# TMS320F280049 register map
Vendor: Texas Instruments; Series: C2000 F28004x; File version: 0.2.0-generated
Registers are 16-bit, read-write, reset 0x0 unless marked. A register's access mark holds for its fields unless they carry their own. Offsets are from the block's base; [hi:lo] are bit positions.

## LINAREGS — LIN Registers
Base 0x0000D400
0x00 SCIGCR0 32-bit — Global Control Register 0
  [0] RESET — LIN Module reset bit
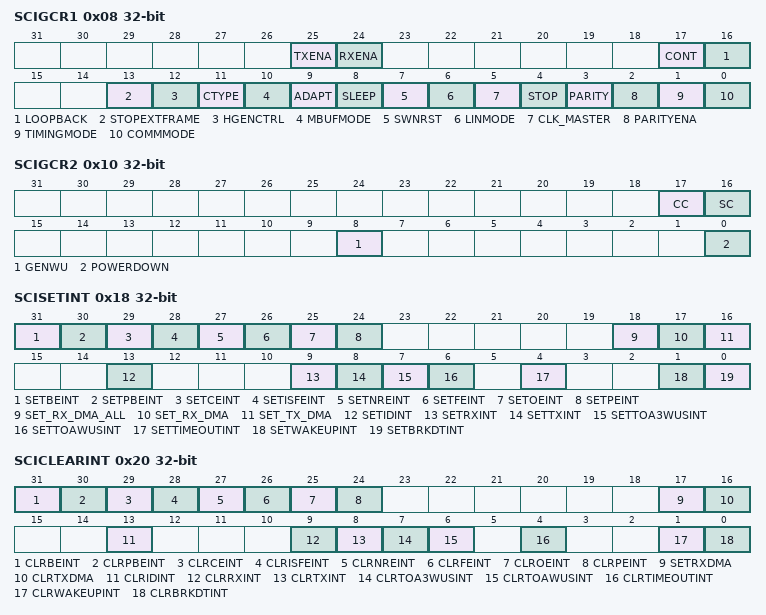
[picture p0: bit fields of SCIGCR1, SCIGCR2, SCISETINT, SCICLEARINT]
0x08 SCIGCR1 32-bit — Global Control Register 1
  [25] TXENA — Transmit enable
  [24] RXENA — Receive enable
  [17] CONT — Continue on suspend
  [16] LOOPBACK — Digital loopback mode
  [13] STOPEXTFRAME — Stop extended frame communication (LIN mode)
  [12] HGENCTRL — Mask filtering comparison control (LIN mode)
  [11] CTYPE — Checksum type (LIN mode)
  [10] MBUFMODE — Multi-buffer mode
  [9] ADAPT — Automatic baudrate adjustment control(LIN mode)
  [8] SLEEP — SCI sleep (SCI compatibility mode)
  [7] SWNRST — Software reset
  [6] LINMODE — LIN Mode enable/disable
  [5] CLK_MASTER — LIN Master/Slave selection and SCI clock enable
  [4] STOP — SCI number of stop bits
  [3] PARITY — SCI parity odd/even selection
  [2] PARITYENA — Parity enable
  [1] TIMINGMODE — SCI timing mode bit. Should be set to 1 for SCI mode.
  [0] COMMMODE — SCI/LIN communications mode bit
0x10 SCIGCR2 32-bit — Global Control Register 2
  [17] CC — Compare Checksum (LIN mode)
  [16] SC — Send Checksum (LIN mode)
  [8] GENWU — Generate Wakeup
  [0] POWERDOWN — Low-power mode PowerDown bit
0x18 SCISETINT 32-bit — Interrupt Enable Register
  [31] SETBEINT — Set Bit Error Interrupt (LIN only)
  [30] SETPBEINT — Set Physical Bus Error Interrupt (LIN only)
  [29] SETCEINT — Set Checksum-error Interrupt (LIN only)
  [28] SETISFEINT — Set Inconsistent-Sync-Field-Error Interrupt (LIN only)
  [27] SETNREINT — Set No-Response-Error Interrupt (LIN only)
  [26] SETFEINT — Set Framing-Error Interrupt
  [25] SETOEINT — Set Overrun-Error Interrupt
  [24] SETPEINT — Set Parity Interrupt
  [18] SET_RX_DMA_ALL — Set receiver DMA for Address and Data frames
  [17] SET_RX_DMA — Set receiver DMA
  [16] SET_TX_DMA — Set transmit DMA
  [13] SETIDINT — Set Identifier Interrupt (LIN only)
  [9] SETRXINT — Se Receiver Interrupt
  [8] SETTXINT — Set Transmitter Interrupt
  [7] SETTOA3WUSINT — Set Timeout After 3 Wakeup Signals Interrupt (LIN only)
  [6] SETTOAWUSINT — Set Timeout After Wakeup Signal Interrupt (LIN only)
  [4] SETTIMEOUTINT — Set Timeout Interrupt (LIN only)
  [1] SETWAKEUPINT — Set Wake-up Interrupt
  [0] SETBRKDTINT — Set Break-detect Interrupt (SCI compatible mode)
0x20 SCICLEARINT 32-bit — Interrupt Disable Register
  [31] CLRBEINT — Clear Bit Error Interrupt (LIN only)
  [30] CLRPBEINT — Clear Physical Bus Error Interrupt (LIN only)
  [29] CLRCEINT — Clear Checksum-error Interrupt (LIN only)
  [28] CLRISFEINT — Clear Inconsistent-Sync-Field-Error Interrupt (LIN only)
  [27] CLRNREINT — Clear No-Response-Error Interrupt (LIN only)
  [26] CLRFEINT — Clear Framing-Error Interrupt
  [25] CLROEINT — Clear Overrun-Error Interrupt
  [24] CLRPEINT — Clear Parity Interrupt
  [17] SETRXDMA — Clear receiver DMA
  [16] CLRTXDMA — Clear transmit DMA
  [13] CLRIDINT — Clear Identifier Interrupt (LIN only)
  [9] CLRRXINT — Clear Receiver Interrupt
  [8] CLRTXINT — Clear Transmitter Interrupt
  [7] CLRTOA3WUSINT — Clear Timeout After 3 Wakeup Signals Interrupt (LIN only)
  [6] CLRTOAWUSINT — Clear Timeout After Wakeup Signal Interrupt (LIN only)
  [4] CLRTIMEOUTINT — Clear Timeout Interrupt (LIN only)
  [1] CLRWAKEUPINT — Clear Wake-up Interrupt
  [0] CLRBRKDTINT — Clear Break-detect Interrupt (SCI compatible mode
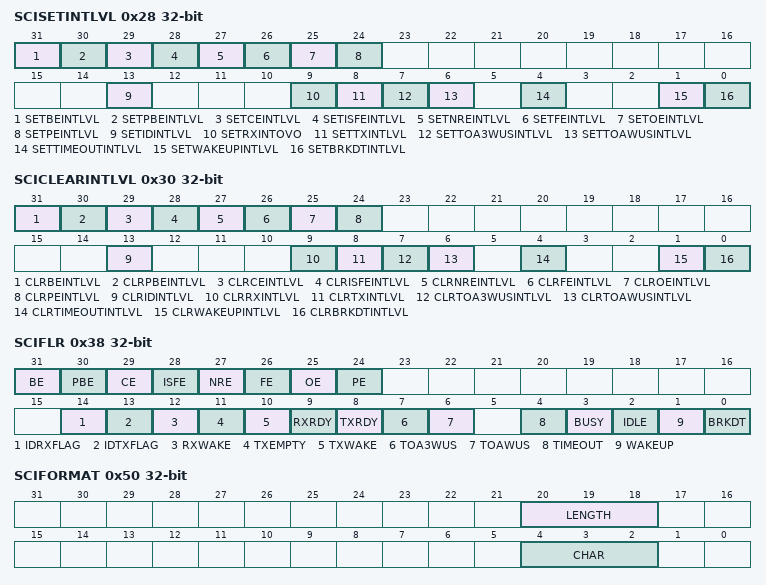
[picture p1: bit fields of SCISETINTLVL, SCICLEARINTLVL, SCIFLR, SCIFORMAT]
0x28 SCISETINTLVL 32-bit — Set Interrupt Level Register
  [31] SETBEINTLVL — Set Bit Error Interrupt Level (LIN only)
  [30] SETPBEINTLVL — Set Physical Bus Error Interrupt Level (LIN only)
  [29] SETCEINTLVL — Set Checksum-error Interrupt Level (LIN only)
  [28] SETISFEINTLVL — Set Inconsistent-Sync-Field-Error Interrupt Level
  [27] SETNREINTLVL — Set No-Response-Error Interrupt Level (LIN only)
  [26] SETFEINTLVL — Set Framing-Error Interrupt Level
  [25] SETOEINTLVL — Set Overrun-Error Interrupt Level
  [24] SETPEINTLVL — Set Parity Interrupt Level
  [13] SETIDINTLVL — Set Identifier Interrupt Level (LIN only)
  [9] SETRXINTOVO — Receiver Interrupt Enable Level
  [8] SETTXINTLVL — Set Transmitter Interrupt Level
  [7] SETTOA3WUSINTLVL — Set Timeout After 3 Wakeup Signals Interrupt Level
  [6] SETTOAWUSINTLVL — Set Timeout After Wakeup Signal Interrupt Level (LIN only)
  [4] SETTIMEOUTINTLVL — Set Timeout Interrupt Level (LIN only)
  [1] SETWAKEUPINTLVL — Set Wake-up Interrupt Level
  [0] SETBRKDTINTLVL — Set Break-detect Interrupt Level (SCI compatible mode)
0x30 SCICLEARINTLVL 32-bit — Clear Interrupt Level Register
  [31] CLRBEINTLVL — Clear Bit Error Interrupt Level (LIN only)
  [30] CLRPBEINTLVL — Clear Physical Bus Error Interrupt Level (LIN only)
  [29] CLRCEINTLVL — Clear Checksum-error Interrupt Level (LIN only)
  [28] CLRISFEINTLVL — Clear Inconsistent-Sync-Field-Error
  [27] CLRNREINTLVL — Clear No-Response-Error Interrupt Level (LIN only)
  [26] CLRFEINTLVL — Clear Framing-Error Interrupt Level
  [25] CLROEINTLVL — Clear Overrun-Error Interrupt Level
  [24] CLRPEINTLVL — Clear Parity Interrupt Level
  [13] CLRIDINTLVL — Clear Identifier Interrupt Level (LIN only)
  [9] CLRRXINTLVL — Clear Receiver interrupt Level.
  [8] CLRTXINTLVL — Clear Transmitter Interrupt Level
  [7] CLRTOA3WUSINTLVL — Clear Timeout After 3 Wakeup Signals
  [6] CLRTOAWUSINTLVL — Clear Timeout After Wakeup Signal Interrupt Level (LIN only)
  [4] CLRTIMEOUTINTLVL — Clear Timeout Interrupt Level (LIN only)
  [1] CLRWAKEUPINTLVL — Clear Wake-up Interrupt Level
  [0] CLRBRKDTINTLVL — Clear Break-detect Interrupt Level (SCI compatible mode)
0x38 SCIFLR 32-bit — Flag Register
  [31] BE — Bit Error Flag (LIN only)
  [30] PBE — Physical Bus Error Flag (LIN only)
  [29] CE — Checksum Error Flag (LIN only)
  [28] ISFE — Inconsistent Sync Field Error Flag (LIN only)
  [27] NRE — No-Response Error Flag (LIN only)
  [26] FE — Framing Error Flag
  [25] OE — Overrun Error Flag
  [24] PE — Parity Error Flag
  [14] IDRXFLAG — Identifier on Receive Flag
  [13] IDTXFLAG — Identifier On Transmit Flag (LIN only)
  [12] RXWAKE — Receiver Wakeup Detect Flag
  [11] TXEMPTY — Transmitter Empty Flag
  [10] TXWAKE — SCI Transmitter Wakeup Method Select
  [9] RXRDY — Receiver Buffer Ready Flag
  [8] TXRDY — Transmitter Buffer Ready Flag
  [7] TOA3WUS — Timeout After 3 Wakeup Signals Flag (LIN only)
  [6] TOAWUS — Timeout After Wakeup Signal Flag (LIN only)
  [4] TIMEOUT — LIN Bus IDLE timeout Flag (LIN only)
  [3] BUSY — Busy Flag
  [2] IDLE — SCI receiver in idle state (SCI compatible mode)
  [1] WAKEUP — Wake-up Flag
  [0] BRKDT — Break-detect Flag (SCI compatible mode)
0x40 SCIINTVECT0 32-bit — Interrupt Vector Offset Register 0
  [8:4] INTVECT0 — LIN Module reset bit
0x48 SCIINTVECT1 32-bit — Interrupt Vector Offset Register 1
  [8:4] INTVECT1 — LIN Module reset bit
0x50 SCIFORMAT 32-bit — Length Control Register
  [20:18] LENGTH — Frame Length Control Bits
  [4:2] CHAR — Character Length Control Bits
0x58 BRSR 32-bit — Baud Rate Selection Register
  [31:30] U — U Superfractional divider Selection
  [30:27] M — M 4-bit Fractional Divider selection
  [30:23] SCI_LIN_PSH — 24-Bit Integer Prescaler Select (High Bits)
  [30:15] SCI_LIN_PSL — 24-Bit Integer Prescaler Select (Low Bits)
0x60 SCIED 32-bit — Emulation buffer Register
  [14:7] ED — Receiver Emulation Data.
0x68 SCIRD 32-bit — Receiver data buffer Register
  [14:7] RD — Received Data.
0x70 SCITD 32-bit — Transmit data buffer Register
  [14:7] TD — Transmit data
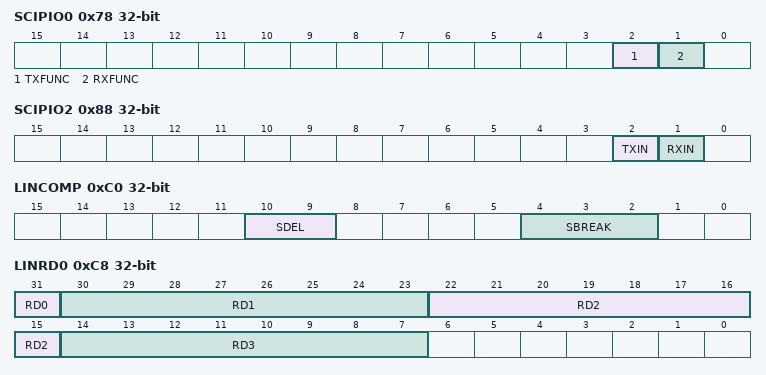
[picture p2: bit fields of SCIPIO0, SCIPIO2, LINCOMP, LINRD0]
0x78 SCIPIO0 32-bit — Pin control Register 0
  [2] TXFUNC — LINTX pin function
  [1] RXFUNC — LINRX pin function
0x88 SCIPIO2 32-bit — Pin control Register 2
  [2] TXIN — SCITX pin value
  [1] RXIN — SCIRX pin value
0xC0 LINCOMP 32-bit — Compare register
  [10:9] SDEL — Sync Delimiter Compare
  [4:2] SBREAK — Sync Break Extend
0xC8 LINRD0 32-bit — Receive data register 0
  [31] RD0 — Receive Buffer 0
  [30:23] RD1 — Receive Buffer 1
  [22:15] RD2 — Receive Buffer 2
  [14:7] RD3 — Receive Buffer 3
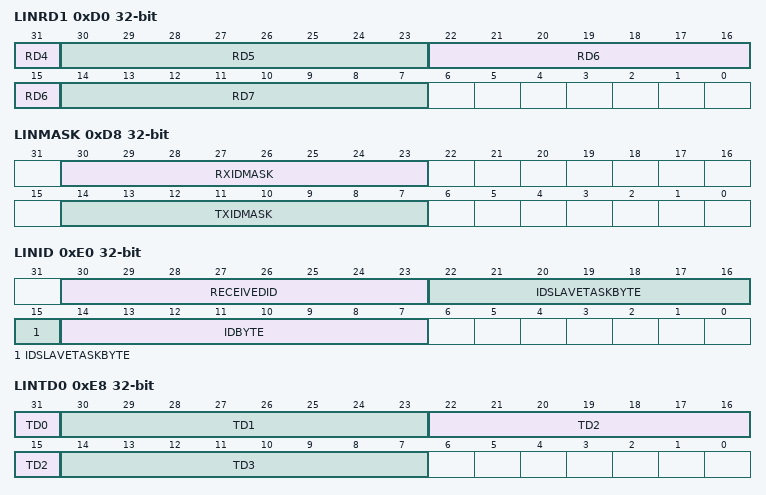
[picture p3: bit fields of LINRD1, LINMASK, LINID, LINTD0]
0xD0 LINRD1 32-bit — Receive data register 1
  [31] RD4 — Receive Buffer 0
  [30:23] RD5 — Receive Buffer 1
  [22:15] RD6 — Receive Buffer 2
  [14:7] RD7 — Receive Buffer 3
0xD8 LINMASK 32-bit — Acceptance mask register
  [30:23] RXIDMASK — RX ID Mask bits (LIN only)
  [14:7] TXIDMASK — TX ID Mask bits (LIN only)
0xE0 LINID 32-bit
  [30:23] RECEIVEDID — Current Message ID (LIN only)
  [22:15] IDSLAVETASKBYTE — ID Slave Task byte (LIN only)
  [14:7] IDBYTE — LIN message ID (LIN only)
0xE8 LINTD0 32-bit — Transmit Data Register 0
  [31] TD0 — TRANSMIT Buffer 0
  [30:23] TD1 — TRANSMIT Buffer 1
  [22:15] TD2 — TRANSMIT Buffer 2
  [14:7] TD3 — TRANSMIT Buffer 3
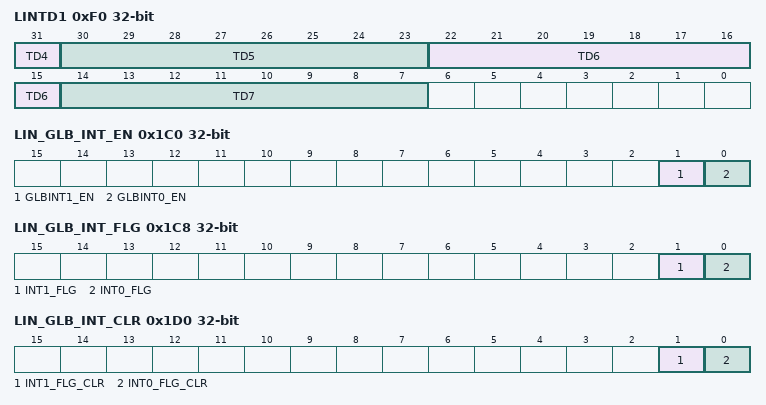
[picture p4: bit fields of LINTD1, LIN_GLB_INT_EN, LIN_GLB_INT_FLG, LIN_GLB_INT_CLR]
0xF0 LINTD1 32-bit — Transmit Data Register 1
  [31] TD4 — TRANSMIT Buffer 4
  [30:23] TD5 — TRANSMIT Buffer 5
  [22:15] TD6 — TRANSMIT Buffer 6
  [14:7] TD7 — TRANSMIT Buffer 7
0xF8 MBRSR 32-bit — Maximum Baud Rate Selection Register
  [24:12] MBR — Received Data.
0x120 IODFTCTRL 32-bit — IODFT for LIN
  [31] BERRENA — Bit Error Enable (LIN mode)
  [30] PBERRENA — Physical Bus Error Enable (LIN mode)
  [29] CERRENA — Checksum Error Enable(LIN mode)
  [28] ISFERRENA — Inconsistent Sync Field Error Enable (LIN mode)
  [26] FERRENA — Frame Error Enable (SCI compatibility mode)
  [25] PERRENA — Parity Error Enable (SCI compatibility mode)
  [24] BRKDTERRENA — Break Detect Error Enable (SCI compatibility mode)
  [21:20] PINSAMPLEMASK — TX Pin Sample Mask
  [20:18] TXSHIFT — Transmit Delay Shift
  [14:11] IODFTENA — IO DFT Enable Key
  [1] LPBENA — Module Loopback Enable
  [0] RXPENA — Analog Loopback Via Receive Pin Enable
0x1C0 LIN_GLB_INT_EN 32-bit — LIN Global Interrupt Enable Register
  [1] GLBINT1_EN — Global Interrupt Enable for LIN INT1
  [0] GLBINT0_EN — Global Interrupt Enable for LIN INT0
0x1C8 LIN_GLB_INT_FLG 32-bit — LIN Global Interrupt Flag Register
  [1] INT1_FLG — Global Interrupt Flag for LIN INT1
  [0] INT0_FLG — Global Interrupt Flag for LIN INT0
0x1D0 LIN_GLB_INT_CLR 32-bit — LIN Global Interrupt Clear Register
  [1] INT1_FLG_CLR — Global Interrupt flag clear for LIN INT1
  [0] INT0_FLG_CLR — Global Interrupt flag clear for LIN INT0
